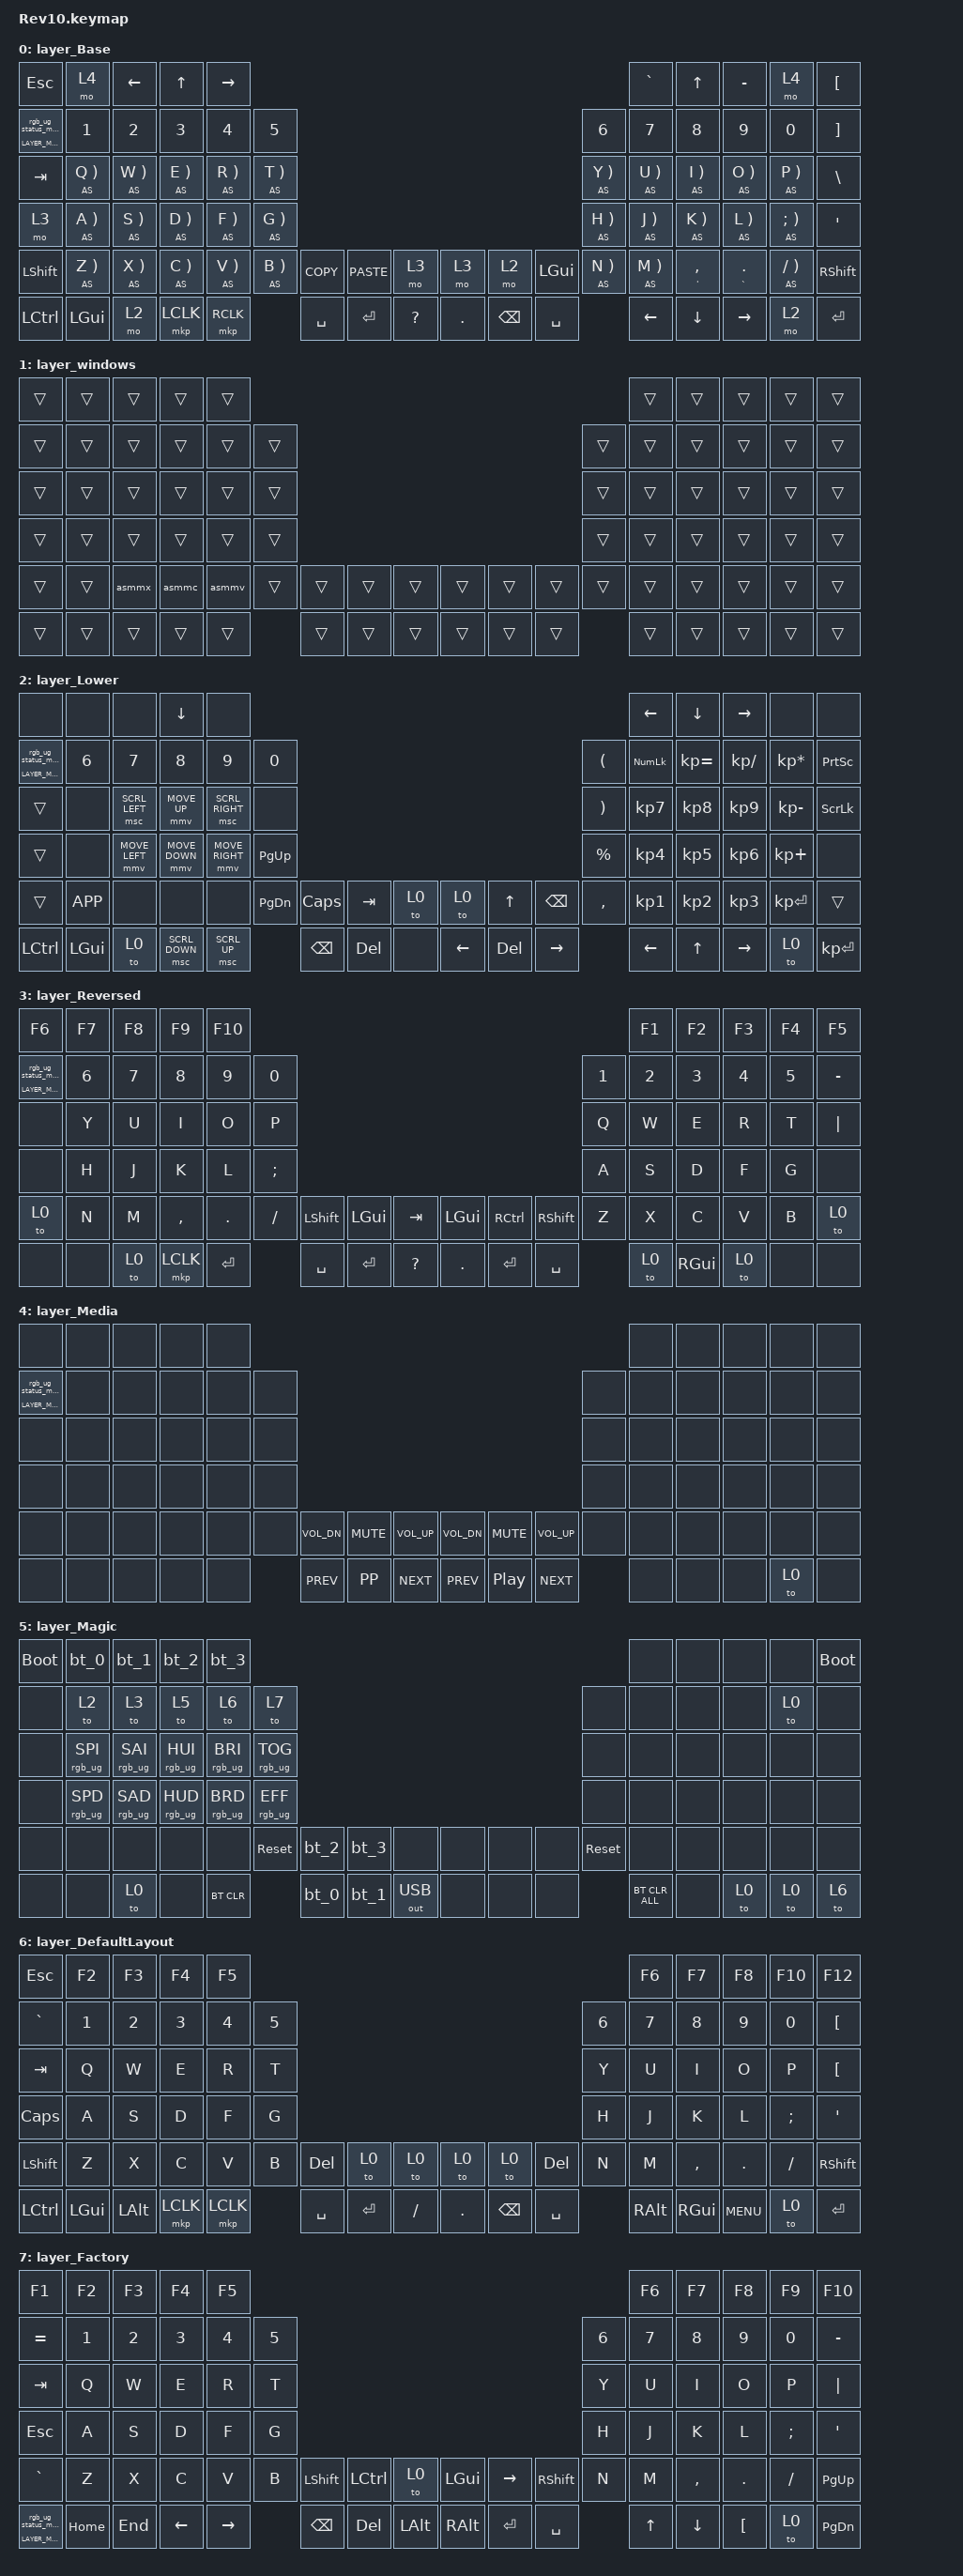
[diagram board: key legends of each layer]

/*
 * Copyright (c) 2020 The ZMK Contributors
 * Copyright (c) 2023 Innaworks Development Limited, trading as MoErgo
 *
 * SPDX-License-Identifier: MIT
 */


/* THIS FILE WAS GENERATED BY GLOVE80 LAYOUT EDITOR
 *
 * This file was generated automatically. You may or may not want to
 * edit it directly.
 */

#include <behaviors.dtsi>
/* Include all behavior includes needed */
#include <dt-bindings/zmk/outputs.h>
#include <dt-bindings/zmk/keys.h>
#include <dt-bindings/zmk/bt.h>
#include <dt-bindings/zmk/rgb.h>

/* Automatically generated layer name #define */
#define LAYER_Base 0
#define LAYER_windows 1
#define LAYER_Lower 2
#define LAYER_Reversed 3
#define LAYER_Media 4
#define LAYER_Magic 5
#define LAYER_DefaultLayout 6
#define LAYER_Factory 7

/* To deal with the situation where there is no Lower layer, to keep &lower happy */
#ifndef LAYER_Lower
#define LAYER_Lower 0
#endif

/* Custom Device-tree */
// KEY_REPEATING_TERM defines how much time you have left (milliseconds)
// after tapping a key to hold it again in order to make it auto-repeat.
#define KEY_REPEATING_TERM 300 // "tap then hold" for key auto-repeat

// TAPPING_TERM defines how long you need to hold (milliseconds)
// mod keys in order to send their modifiers to the computer
// (i.e. "register" them) for mod-click mouse usage (e.g. Ctrl-Click).
#define TAPPING_TERM 260 // TAPPING_TERM + ALLOW_CROSSOVER_AFTER
    
// AUTO_SHIFT_TERM defines how long you need to hold (milliseconds)
// a key in order to send its shifted version to the computer.
#define AUTO_SHIFT_TERM 200 // AUTO_SHIFT_TERM + ALLOW_CROSSOVER_AFTER

&mt {
    flavor = "hold-preferred";
    tapping-term-ms = <TAPPING_TERM>;
    quick-tap-ms = <KEY_REPEATING_TERM>;
};

&lt {
    flavor = "hold-preferred";
    tapping-term-ms = <TAPPING_TERM>;
    quick-tap-ms = <KEY_REPEATING_TERM>;
};


/* Glove80 system behavior & macros */
/ {
    behaviors {
        // For the "layer" key, it'd nice to be able to use it as either a shift or a toggle.
        // Configure it as a tap dance, so the first tap (or hold) is a &mo and the second tap is a &to
        lower: lower {
            compatible = "zmk,behavior-tap-dance";
            label = "LAYER_TAP_DANCE";
            #binding-cells = <0>;
            tapping-term-ms = <200>;
            bindings = <&mo LAYER_Lower>, <&to LAYER_Lower>;
        };
    };
};

/ {
    macros {
        rgb_ug_status_macro: rgb_ug_status_macro {
            label = "RGB_UG_STATUS";
            compatible = "zmk,behavior-macro";
            #binding-cells = <0>;
            bindings
                = <&rgb_ug RGB_STATUS>;
        };
    };
};


/ {
#ifdef BT_DISC_CMD
    behaviors {
        bt_0: bt_0 {
            compatible = "zmk,behavior-tap-dance";
            label = "BT_0";
            #binding-cells = <0>;
            tapping-term-ms = <200>;
            bindings = <&bt_select_0>, <&bt BT_DISC 0>;
        };
        bt_1: bt_1 {
            compatible = "zmk,behavior-tap-dance";
            label = "BT_1";
            #binding-cells = <0>;
            tapping-term-ms = <200>;
            bindings = <&bt_select_1>, <&bt BT_DISC 1>;
        };
        bt_2: bt_2 {
            compatible = "zmk,behavior-tap-dance";
            label = "BT_2";
            #binding-cells = <0>;
            tapping-term-ms = <200>;
            bindings = <&bt_select_2>, <&bt BT_DISC 2>;
        };
        bt_3: bt_3 {
            compatible = "zmk,behavior-tap-dance";
            label = "BT_3";
            #binding-cells = <0>;
            tapping-term-ms = <200>;
            bindings = <&bt_select_3>, <&bt BT_DISC 3>;
        };
    };
    macros {
        bt_select_0: bt_select_0 {
            label = "BT_SELECT_0";
            compatible = "zmk,behavior-macro";
            #binding-cells = <0>;
            bindings
                = <&out OUT_BLE>,
                  <&bt BT_SEL 0>;
        };
        bt_select_1: bt_select_1 {
            label = "BT_SELECT_1";
            compatible = "zmk,behavior-macro";
            #binding-cells = <0>;
            bindings
                = <&out OUT_BLE>,
                  <&bt BT_SEL 1>;
        };
        bt_select_2: bt_select_2 {
            label = "BT_SELECT_2";
            compatible = "zmk,behavior-macro";
            #binding-cells = <0>;
            bindings
                = <&out OUT_BLE>,
                  <&bt BT_SEL 2>;
        };
        bt_select_3: bt_select_3 {
            label = "BT_SELECT_3";
            compatible = "zmk,behavior-macro";
            #binding-cells = <0>;
            bindings
                = <&out OUT_BLE>,
                  <&bt BT_SEL 3>;
        };
    };
#else
    macros {
        bt_0: bt_0 {
            label = "BT_0";
            compatible = "zmk,behavior-macro";
            #binding-cells = <0>;
            bindings
                = <&out OUT_BLE>,
                  <&bt BT_SEL 0>;
        };
        bt_1: bt_1 {
            label = "BT_1";
            compatible = "zmk,behavior-macro";
            #binding-cells = <0>;
            bindings
                = <&out OUT_BLE>,
                  <&bt BT_SEL 1>;
        };
        bt_2: bt_2 {
            label = "BT_2";
            compatible = "zmk,behavior-macro";
            #binding-cells = <0>;
            bindings
                = <&out OUT_BLE>,
                  <&bt BT_SEL 2>;
        };
        bt_3: bt_3 {
            label = "BT_3";
            compatible = "zmk,behavior-macro";
            #binding-cells = <0>;
            bindings
                = <&out OUT_BLE>,
                  <&bt BT_SEL 3>;
        };
    };
#endif
};

/ {
    behaviors {
        magic: magic {
            compatible = "zmk,behavior-hold-tap";
            label = "MAGIC_HOLD_TAP";
            #binding-cells = <2>;
            flavor = "tap-preferred";
            tapping-term-ms = <200>;
            bindings = <&mo>, <&rgb_ug_status_macro>;
        };
    };
};

/* #define for key positions */
#define POS_LH_T1 52
#define POS_LH_T2 53
#define POS_LH_T3 54
#define POS_LH_T4 69
#define POS_LH_T5 70
#define POS_LH_T6 71
#define POS_LH_C1R2 15
#define POS_LH_C1R3 27
#define POS_LH_C1R4 39
#define POS_LH_C1R5 51
#define POS_LH_C2R1 4
#define POS_LH_C2R2 14
#define POS_LH_C2R3 26
#define POS_LH_C2R4 38
#define POS_LH_C2R5 50
#define POS_LH_C2R6 68
#define POS_LH_C3R1 3
#define POS_LH_C3R2 13
#define POS_LH_C3R3 25
#define POS_LH_C3R4 37
#define POS_LH_C3R5 49
#define POS_LH_C3R6 67
#define POS_LH_C4R1 2
#define POS_LH_C4R2 12
#define POS_LH_C4R3 24
#define POS_LH_C4R4 36
#define POS_LH_C4R5 48
#define POS_LH_C4R6 66
#define POS_LH_C5R1 1
#define POS_LH_C5R2 11
#define POS_LH_C5R3 23
#define POS_LH_C5R4 35
#define POS_LH_C5R5 47
#define POS_LH_C5R6 65
#define POS_LH_C6R1 0
#define POS_LH_C6R2 10
#define POS_LH_C6R3 22
#define POS_LH_C6R4 34
#define POS_LH_C6R5 46
#define POS_LH_C6R6 64
#define POS_RH_T1 57
#define POS_RH_T2 56
#define POS_RH_T3 55
#define POS_RH_T4 74
#define POS_RH_T5 73
#define POS_RH_T6 72
#define POS_RH_C1R2 16
#define POS_RH_C1R3 28
#define POS_RH_C1R4 40
#define POS_RH_C1R5 58
#define POS_RH_C2R1 5
#define POS_RH_C2R2 17
#define POS_RH_C2R3 29
#define POS_RH_C2R4 41
#define POS_RH_C2R5 59
#define POS_RH_C2R6 75
#define POS_RH_C3R1 6
#define POS_RH_C3R2 18
#define POS_RH_C3R3 30
#define POS_RH_C3R4 42
#define POS_RH_C3R5 60
#define POS_RH_C3R6 76
#define POS_RH_C4R1 7
#define POS_RH_C4R2 19
#define POS_RH_C4R3 31
#define POS_RH_C4R4 43
#define POS_RH_C4R5 61
#define POS_RH_C4R6 77
#define POS_RH_C5R1 8
#define POS_RH_C5R2 20
#define POS_RH_C5R3 32
#define POS_RH_C5R4 44
#define POS_RH_C5R5 62
#define POS_RH_C5R6 78
#define POS_RH_C6R1 9
#define POS_RH_C6R2 21
#define POS_RH_C6R3 33
#define POS_RH_C6R4 45
#define POS_RH_C6R5 63
#define POS_RH_C6R6 79

/* Custom Defined Behaviors */
/ {
// NOTE: Use the `#define` settings below to customize this keymap!
// For example, here are the main optional features you can enable:
#define DIFFICULTY_LEVEL  1 // 0:custom, 1:easy -> 5:hard (see below)
// TIP: Add more setting overrides here instead of editing them below.

//////////////////////////////////////////////////////////////////////////////
//
// Advanced Home Row Mods (HRM) Example based on
// Sunaku's Keymap v35 -- "Glorious Engrammer"
// - https://github.com/sunaku/glove80-keymaps
//
//////////////////////////////////////////////////////////////////////////////

//
// DIFFICULTY_LEVEL specifies your level of expertise with this keymap.
// It's meant to help newcomers gradually work their way up to mastery.
// You can disable this setting by omitting it or assigning a `0` zero.
//
// #define DIFFICULTY_LEVEL 0 // custom (see defaults below)
// #define DIFFICULTY_LEVEL 1 // novice (500ms)
// #define DIFFICULTY_LEVEL 2 // slower (400ms)
// #define DIFFICULTY_LEVEL 3 // normal (300ms)
// #define DIFFICULTY_LEVEL 4 // faster (200ms)
// #define DIFFICULTY_LEVEL 5 // expert (100ms)
//
#if defined(DIFFICULTY_LEVEL) && DIFFICULTY_LEVEL > 0
#define DIFFICULTY_THRESHOLD ((6-DIFFICULTY_LEVEL)*100)
#ifndef HOMEY_HOLDING_TIME
#define HOMEY_HOLDING_TIME DIFFICULTY_THRESHOLD
#endif
#ifndef INDEX_HOLDING_TIME
#define INDEX_HOLDING_TIME DIFFICULTY_THRESHOLD
#endif
#endif

behaviors {

    //////////////////////////////////////////////////////////////////////////
    //
    // Miryoku layers and home row mods (ported from my QMK endgame)
    // - https://sunaku.github.io/home-row-mods.html#porting-to-zmk
    // - https://github.com/urob/zmk-config#timeless-homerow-mods
    //
    //////////////////////////////////////////////////////////////////////////

    //
    // HOMEY_HOLDING_TYPE defines the flavor of ZMK hold-tap behavior to use
    // for the pinky, ring, and middle fingers (which are assigned to Super,
    // Alt, and Ctrl respectively in the Miryoku system) on home row keys.
    //
    #ifndef HOMEY_HOLDING_TYPE
    #define HOMEY_HOLDING_TYPE "tap-preferred"
    #endif

    //
    // HOMEY_HOLDING_TIME defines how long you need to hold (milliseconds)
    // home row mod keys in order to send their modifiers to the computer
    // (i.e. "register" them) for mod-click mouse usage (e.g. Ctrl-Click).
    //
    #ifndef HOMEY_HOLDING_TIME
    #define HOMEY_HOLDING_TIME 270 // TAPPING_TERM + ALLOW_CROSSOVER_AFTER
    #endif

    //
    // HOMEY_STREAK_DECAY defines how long you need to wait (milliseconds)
    // after typing before you can use home row mods again.  It prevents
    // unintended activation of home row mods when you're actively typing.
    //
    #ifndef HOMEY_STREAK_DECAY
    #define HOMEY_STREAK_DECAY 250
    #endif

    //
    // HOMEY_REPEAT_DECAY defines how much time you have left (milliseconds)
    // after tapping a key to hold it again in order to make it auto-repeat.
    //
    #ifndef HOMEY_REPEAT_DECAY
    #define HOMEY_REPEAT_DECAY 300 // "tap then hold" for key auto-repeat
    #endif

    //
    // INDEX_HOLDING_TYPE defines the flavor of ZMK hold-tap behavior to use
    // for index fingers (which Miryoku assigns to Shift) on home row keys.
    //
    #ifndef INDEX_HOLDING_TYPE
    #define INDEX_HOLDING_TYPE "tap-preferred"
    #endif

    //
    // INDEX_HOLDING_TIME defines how long you need to hold (milliseconds)
    // index finger keys in order to send their modifiers to the computer
    // (i.e. "register" them) for mod-click mouse usage (e.g. Shift-Click).
    //
    #ifndef INDEX_HOLDING_TIME
    #define INDEX_HOLDING_TIME 170
    #endif

    //
    // INDEX_STREAK_DECAY defines how long you need to wait (milliseconds)
    // after typing before you can use home row mods again.  It prevents
    // unintended activation of home row mods when you're actively typing.
    //
    #ifndef INDEX_STREAK_DECAY
    #define INDEX_STREAK_DECAY 150
    #endif

    //
    // INDEX_REPEAT_DECAY defines how much time you have left (milliseconds)
    // after tapping a key to hold it again in order to make it auto-repeat.
    //
    #ifndef INDEX_REPEAT_DECAY
    #define INDEX_REPEAT_DECAY 300 // "tap then hold" for key auto-repeat
    #endif

    //
    // Glove80 key positions index for positional hold-tap
    // - https://discord.com/channels/877392805654306816/937645688244826154/1066713913351221248
    // - https://media.discordapp.net/attachments/937645688244826154/1066713913133121556/image.png
    //
    // |------------------------|------------------------|
    // | LEFT_HAND_KEYS         |        RIGHT_HAND_KEYS |
    // |                        |                        |
    // |  0  1  2  3  4         |          5  6  7  8  9 |
    // | 10 11 12 13 14 15      |      16 17 18 19 20 21 |
    // | 22 23 24 25 26 27      |      28 29 30 31 32 33 |
    // | 34 35 36 37 38 39      |      40 41 42 43 44 45 |
    // | 46 47 48 49 50 51      |      58 59 60 61 62 63 |
    // | 64 65 66 67 68         |         75 76 77 78 79 |
    // |                69 52   |   57 74                |
    // |                 70 53  |  56 73                 |
    // |                  71 54 | 55 72                  |
    // |------------------------|------------------------|
    //
    #define LEFT_HAND_KEYS      \
          0  1  2  3  4         \
         10 11 12 13 14 15      \
         22 23 24 25 26 27      \
         34 35 36 37 38 39      \
         46 47 48 49 50 51      \
         64 65 66 67 68
    #define RIGHT_HAND_KEYS     \
                                           5  6  7  8  9 \
                                       16 17 18 19 20 21 \
                                       28 29 30 31 32 33 \
                                       40 41 42 43 44 45 \
                                       58 59 60 61 62 63 \
                                          75 76 77 78 79
    #define THUMB_KEYS          \
                        69 52       57 74                \
                         70 53     56 73                 \
                          71 54   55 72

    //
    // Home row mods with per-finger configuration settings
    //
    #ifndef PINKY_HOLDING_TYPE
    #define PINKY_HOLDING_TYPE HOMEY_HOLDING_TYPE
    #endif
    #ifndef PINKY_HOLDING_TIME
    #define PINKY_HOLDING_TIME HOMEY_HOLDING_TIME
    #endif
    #ifndef PINKY_STREAK_DECAY
    #define PINKY_STREAK_DECAY HOMEY_STREAK_DECAY
    #endif
    #ifndef PINKY_REPEAT_DECAY
    #define PINKY_REPEAT_DECAY HOMEY_REPEAT_DECAY
    #endif
    #ifndef RING1_HOLDING_TYPE
    #define RING1_HOLDING_TYPE HOMEY_HOLDING_TYPE
    #endif
    #ifndef RING1_HOLDING_TIME
    #define RING1_HOLDING_TIME HOMEY_HOLDING_TIME
    #endif
    #ifndef RING1_STREAK_DECAY
    #define RING1_STREAK_DECAY HOMEY_STREAK_DECAY
    #endif
    #ifndef RING1_REPEAT_DECAY
    #define RING1_REPEAT_DECAY HOMEY_REPEAT_DECAY
    #endif
    #ifndef RING2_HOLDING_TYPE
    #define RING2_HOLDING_TYPE HOMEY_HOLDING_TYPE
    #endif
    #ifndef RING2_HOLDING_TIME
    #define RING2_HOLDING_TIME HOMEY_HOLDING_TIME
    #endif
    #ifndef RING2_STREAK_DECAY
    #define RING2_STREAK_DECAY HOMEY_STREAK_DECAY
    #endif
    #ifndef RING2_REPEAT_DECAY
    #define RING2_REPEAT_DECAY HOMEY_REPEAT_DECAY
    #endif
    #ifndef MIDDY_HOLDING_TYPE
    #define MIDDY_HOLDING_TYPE HOMEY_HOLDING_TYPE
    #endif
    #ifndef MIDDY_HOLDING_TIME
    #define MIDDY_HOLDING_TIME HOMEY_HOLDING_TIME
    #endif
    #ifndef MIDDY_STREAK_DECAY
    #define MIDDY_STREAK_DECAY HOMEY_STREAK_DECAY
    #endif
    #ifndef MIDDY_REPEAT_DECAY
    #define MIDDY_REPEAT_DECAY HOMEY_REPEAT_DECAY
    #endif
    #ifndef INDEX_HOLDING_TYPE
    #define INDEX_HOLDING_TYPE HOMEY_HOLDING_TYPE
    #endif
    #ifndef INDEX_HOLDING_TIME
    #define INDEX_HOLDING_TIME HOMEY_HOLDING_TIME
    #endif
    #ifndef INDEX_STREAK_DECAY
    #define INDEX_STREAK_DECAY HOMEY_STREAK_DECAY
    #endif
    #ifndef INDEX_REPEAT_DECAY
    #define INDEX_REPEAT_DECAY HOMEY_REPEAT_DECAY
    #endif
    #ifndef LEFT_PINKY_HOLDING_TYPE
    #define LEFT_PINKY_HOLDING_TYPE PINKY_HOLDING_TYPE
    #endif
    #ifndef LEFT_PINKY_HOLDING_TIME
    #define LEFT_PINKY_HOLDING_TIME PINKY_HOLDING_TIME
    #endif
    #ifndef LEFT_PINKY_STREAK_DECAY
    #define LEFT_PINKY_STREAK_DECAY PINKY_STREAK_DECAY
    #endif
    #ifndef LEFT_PINKY_REPEAT_DECAY
    #define LEFT_PINKY_REPEAT_DECAY PINKY_REPEAT_DECAY
    #endif
    left_pinky: homey_left_pinky {
        compatible = "zmk,behavior-hold-tap";
        flavor = LEFT_PINKY_HOLDING_TYPE;
        hold-trigger-key-positions = <RIGHT_HAND_KEYS THUMB_KEYS>;
        hold-trigger-on-release; // wait for other home row mods
        tapping-term-ms = <LEFT_PINKY_HOLDING_TIME>;
        quick-tap-ms = <LEFT_PINKY_REPEAT_DECAY>;
        require-prior-idle-ms = <LEFT_PINKY_STREAK_DECAY>;
        #binding-cells = <2>;
        bindings = <&kp>, <&kp>;
    };
    #ifndef RIGHT_PINKY_HOLDING_TYPE
    #define RIGHT_PINKY_HOLDING_TYPE PINKY_HOLDING_TYPE
    #endif
    #ifndef RIGHT_PINKY_HOLDING_TIME
    #define RIGHT_PINKY_HOLDING_TIME PINKY_HOLDING_TIME
    #endif
    #ifndef RIGHT_PINKY_STREAK_DECAY
    #define RIGHT_PINKY_STREAK_DECAY PINKY_STREAK_DECAY
    #endif
    #ifndef RIGHT_PINKY_REPEAT_DECAY
    #define RIGHT_PINKY_REPEAT_DECAY PINKY_REPEAT_DECAY
    #endif
    right_pinky: homey_right_pinky {
        compatible = "zmk,behavior-hold-tap";
        flavor = RIGHT_PINKY_HOLDING_TYPE;
        hold-trigger-key-positions = <LEFT_HAND_KEYS THUMB_KEYS>;
        hold-trigger-on-release; // wait for other home row mods
        tapping-term-ms = <RIGHT_PINKY_HOLDING_TIME>;
        quick-tap-ms = <RIGHT_PINKY_REPEAT_DECAY>;
        require-prior-idle-ms = <RIGHT_PINKY_STREAK_DECAY>;
        #binding-cells = <2>;
        bindings = <&kp>, <&kp>;
    };
    #ifndef LEFT_RING1_HOLDING_TYPE
    #define LEFT_RING1_HOLDING_TYPE RING1_HOLDING_TYPE
    #endif
    #ifndef LEFT_RING1_HOLDING_TIME
    #define LEFT_RING1_HOLDING_TIME RING1_HOLDING_TIME
    #endif
    #ifndef LEFT_RING1_STREAK_DECAY
    #define LEFT_RING1_STREAK_DECAY RING1_STREAK_DECAY
    #endif
    #ifndef LEFT_RING1_REPEAT_DECAY
    #define LEFT_RING1_REPEAT_DECAY RING1_REPEAT_DECAY
    #endif
    left_ring1: homey_left_ring1 {
        compatible = "zmk,behavior-hold-tap";
        flavor = LEFT_RING1_HOLDING_TYPE;
        hold-trigger-key-positions = <RIGHT_HAND_KEYS THUMB_KEYS>;
        hold-trigger-on-release; // wait for other home row mods
        tapping-term-ms = <LEFT_RING1_HOLDING_TIME>;
        quick-tap-ms = <LEFT_RING1_REPEAT_DECAY>;
        require-prior-idle-ms = <LEFT_RING1_STREAK_DECAY>;
        #binding-cells = <2>;
        bindings = <&kp>, <&kp>;
    };
    #ifndef RIGHT_RING1_HOLDING_TYPE
    #define RIGHT_RING1_HOLDING_TYPE RING1_HOLDING_TYPE
    #endif
    #ifndef RIGHT_RING1_HOLDING_TIME
    #define RIGHT_RING1_HOLDING_TIME RING1_HOLDING_TIME
    #endif
    #ifndef RIGHT_RING1_STREAK_DECAY
    #define RIGHT_RING1_STREAK_DECAY RING1_STREAK_DECAY
    #endif
    #ifndef RIGHT_RING1_REPEAT_DECAY
    #define RIGHT_RING1_REPEAT_DECAY RING1_REPEAT_DECAY
    #endif
    right_ring1: homey_right_ring1 {
        compatible = "zmk,behavior-hold-tap";
        flavor = RIGHT_RING1_HOLDING_TYPE;
        hold-trigger-key-positions = <LEFT_HAND_KEYS THUMB_KEYS>;
        hold-trigger-on-release; // wait for other home row mods
        tapping-term-ms = <RIGHT_RING1_HOLDING_TIME>;
        quick-tap-ms = <RIGHT_RING1_REPEAT_DECAY>;
        require-prior-idle-ms = <RIGHT_RING1_STREAK_DECAY>;
        #binding-cells = <2>;
        bindings = <&kp>, <&kp>;
    };
    #ifndef LEFT_RING2_HOLDING_TYPE
    #define LEFT_RING2_HOLDING_TYPE RING2_HOLDING_TYPE
    #endif
    #ifndef LEFT_RING2_HOLDING_TIME
    #define LEFT_RING2_HOLDING_TIME RING2_HOLDING_TIME
    #endif
    #ifndef LEFT_RING2_STREAK_DECAY
    #define LEFT_RING2_STREAK_DECAY RING2_STREAK_DECAY
    #endif
    #ifndef LEFT_RING2_REPEAT_DECAY
    #define LEFT_RING2_REPEAT_DECAY RING2_REPEAT_DECAY
    #endif
    left_ring2: homey_left_ring2 {
        compatible = "zmk,behavior-hold-tap";
        flavor = LEFT_RING2_HOLDING_TYPE;
        hold-trigger-key-positions = <RIGHT_HAND_KEYS THUMB_KEYS>;
        hold-trigger-on-release; // wait for other home row mods
        tapping-term-ms = <LEFT_RING2_HOLDING_TIME>;
        quick-tap-ms = <LEFT_RING2_REPEAT_DECAY>;
        require-prior-idle-ms = <LEFT_RING2_STREAK_DECAY>;
        #binding-cells = <2>;
        bindings = <&kp>, <&kp>;
    };
    #ifndef RIGHT_RING2_HOLDING_TYPE
    #define RIGHT_RING2_HOLDING_TYPE RING2_HOLDING_TYPE
    #endif
    #ifndef RIGHT_RING2_HOLDING_TIME
    #define RIGHT_RING2_HOLDING_TIME RING2_HOLDING_TIME
    #endif
    #ifndef RIGHT_RING2_STREAK_DECAY
    #define RIGHT_RING2_STREAK_DECAY RING2_STREAK_DECAY
    #endif
    #ifndef RIGHT_RING2_REPEAT_DECAY
    #define RIGHT_RING2_REPEAT_DECAY RING2_REPEAT_DECAY
    #endif
    right_ring2: homey_right_ring2 {
        compatible = "zmk,behavior-hold-tap";
        flavor = RIGHT_RING2_HOLDING_TYPE;
        hold-trigger-key-positions = <LEFT_HAND_KEYS THUMB_KEYS>;
        hold-trigger-on-release; // wait for other home row mods
        tapping-term-ms = <RIGHT_RING2_HOLDING_TIME>;
        quick-tap-ms = <RIGHT_RING2_REPEAT_DECAY>;
        require-prior-idle-ms = <RIGHT_RING2_STREAK_DECAY>;
        #binding-cells = <2>;
        bindings = <&kp>, <&kp>;
    };
    #ifndef LEFT_MIDDY_HOLDING_TYPE
    #define LEFT_MIDDY_HOLDING_TYPE MIDDY_HOLDING_TYPE
    #endif
    #ifndef LEFT_MIDDY_HOLDING_TIME
    #define LEFT_MIDDY_HOLDING_TIME MIDDY_HOLDING_TIME
    #endif
    #ifndef LEFT_MIDDY_STREAK_DECAY
    #define LEFT_MIDDY_STREAK_DECAY MIDDY_STREAK_DECAY
    #endif
    #ifndef LEFT_MIDDY_REPEAT_DECAY
    #define LEFT_MIDDY_REPEAT_DECAY MIDDY_REPEAT_DECAY
    #endif
    left_middy: homey_left_middy {
        compatible = "zmk,behavior-hold-tap";
        flavor = LEFT_MIDDY_HOLDING_TYPE;
        hold-trigger-key-positions = <RIGHT_HAND_KEYS THUMB_KEYS>;
        hold-trigger-on-release; // wait for other home row mods
        tapping-term-ms = <LEFT_MIDDY_HOLDING_TIME>;
        quick-tap-ms = <LEFT_MIDDY_REPEAT_DECAY>;
        require-prior-idle-ms = <LEFT_MIDDY_STREAK_DECAY>;
        #binding-cells = <2>;
        bindings = <&kp>, <&kp>;
    };
    #ifndef RIGHT_MIDDY_HOLDING_TYPE
    #define RIGHT_MIDDY_HOLDING_TYPE MIDDY_HOLDING_TYPE
    #endif
    #ifndef RIGHT_MIDDY_HOLDING_TIME
    #define RIGHT_MIDDY_HOLDING_TIME MIDDY_HOLDING_TIME
    #endif
    #ifndef RIGHT_MIDDY_STREAK_DECAY
    #define RIGHT_MIDDY_STREAK_DECAY MIDDY_STREAK_DECAY
    #endif
    #ifndef RIGHT_MIDDY_REPEAT_DECAY
    #define RIGHT_MIDDY_REPEAT_DECAY MIDDY_REPEAT_DECAY
    #endif
    right_middy: homey_right_middy {
        compatible = "zmk,behavior-hold-tap";
        flavor = RIGHT_MIDDY_HOLDING_TYPE;
        hold-trigger-key-positions = <LEFT_HAND_KEYS THUMB_KEYS>;
        hold-trigger-on-release; // wait for other home row mods
        tapping-term-ms = <RIGHT_MIDDY_HOLDING_TIME>;
        quick-tap-ms = <RIGHT_MIDDY_REPEAT_DECAY>;
        require-prior-idle-ms = <RIGHT_MIDDY_STREAK_DECAY>;
        #binding-cells = <2>;
        bindings = <&kp>, <&kp>;
    };
    #ifndef LEFT_INDEX_HOLDING_TYPE
    #define LEFT_INDEX_HOLDING_TYPE INDEX_HOLDING_TYPE
    #endif
    #ifndef LEFT_INDEX_HOLDING_TIME
    #define LEFT_INDEX_HOLDING_TIME INDEX_HOLDING_TIME
    #endif
    #ifndef LEFT_INDEX_STREAK_DECAY
    #define LEFT_INDEX_STREAK_DECAY INDEX_STREAK_DECAY
    #endif
    #ifndef LEFT_INDEX_REPEAT_DECAY
    #define LEFT_INDEX_REPEAT_DECAY INDEX_REPEAT_DECAY
    #endif
    left_index: homey_left_index {
        compatible = "zmk,behavior-hold-tap";
        flavor = LEFT_INDEX_HOLDING_TYPE;
        hold-trigger-key-positions = <RIGHT_HAND_KEYS THUMB_KEYS>;
        hold-trigger-on-release; // wait for other home row mods
        tapping-term-ms = <LEFT_INDEX_HOLDING_TIME>;
        quick-tap-ms = <LEFT_INDEX_REPEAT_DECAY>;
        require-prior-idle-ms = <LEFT_INDEX_STREAK_DECAY>;
        #binding-cells = <2>;
        bindings = <&kp>, <&kp>;
    };
    #ifndef RIGHT_INDEX_HOLDING_TYPE
    #define RIGHT_INDEX_HOLDING_TYPE INDEX_HOLDING_TYPE
    #endif
    #ifndef RIGHT_INDEX_HOLDING_TIME
    #define RIGHT_INDEX_HOLDING_TIME INDEX_HOLDING_TIME
    #endif
    #ifndef RIGHT_INDEX_STREAK_DECAY
    #define RIGHT_INDEX_STREAK_DECAY INDEX_STREAK_DECAY
    #endif
    #ifndef RIGHT_INDEX_REPEAT_DECAY
    #define RIGHT_INDEX_REPEAT_DECAY INDEX_REPEAT_DECAY
    #endif
    right_index: homey_right_index {
        compatible = "zmk,behavior-hold-tap";
        flavor = RIGHT_INDEX_HOLDING_TYPE;
        hold-trigger-key-positions = <LEFT_HAND_KEYS THUMB_KEYS>;
        hold-trigger-on-release; // wait for other home row mods
        tapping-term-ms = <RIGHT_INDEX_HOLDING_TIME>;
        quick-tap-ms = <RIGHT_INDEX_REPEAT_DECAY>;
        require-prior-idle-ms = <RIGHT_INDEX_STREAK_DECAY>;
        #binding-cells = <2>;
        bindings = <&kp>, <&kp>;
    };

};

//////////////////////////////////////////////////////////////////////////
//
// Mouse keys (control mouse via keyboard) -- requires PR23 beta firmware:
// select "community.pr23.mouse-keys" from the drop-down menu located at
// Glove80 Layout Editor > Settings > Advanced Settings > Firmware Version
//
// - https://github.com/moergo-sc/zmk/pull/23
// - https://gist.github.com/krissen/dd27082e7ab0575619c7a31f4d2ec7ae
// - https://github.com/zmkfirmware/zmk/compare/main...urob:zmk:mouse-3.2
//
//////////////////////////////////////////////////////////////////////////

//
// MOUSE_MOTION_DELAY defines how long to wait (milliseconds) before starting
// to move the mouse pointer.
//
#ifndef MOUSE_MOTION_DELAY
#define MOUSE_MOTION_DELAY 0
#endif

//
// MOUSE_MOTION_ACCELERATION_EXPONENT sets how the mouse pointer accelerates:
//
// acceleration exponent 0: uniform speed
// acceleration exponent 1: uniform acceleration
// acceleration exponent 2: uniform jerk
//
#ifndef MOUSE_MOTION_ACCELERATION_EXPONENT
#define MOUSE_MOTION_ACCELERATION_EXPONENT 1
#endif

//
// MOUSE_MOTION_TIME_TO_MAXIMUM_SPEED defines how long to wait (milliseconds)
// before the mouse pointer speed is suddenly boosted to the maximum value.
//
#ifndef MOUSE_MOTION_TIME_TO_MAXIMUM_SPEED
#define MOUSE_MOTION_TIME_TO_MAXIMUM_SPEED 300
#endif

//
// MOUSE_MOTION_MAXIMUM_SPEED defines how quickly the mouse pointer can move.
//
#ifndef MOUSE_MOTION_MAXIMUM_SPEED
#define MOUSE_MOTION_MAXIMUM_SPEED 600
#endif

//
// MOUSE_SCROLL_DELAY defines how long to wait (milliseconds) before starting
// to move the mouse pointer.
//
#ifndef MOUSE_SCROLL_DELAY
#define MOUSE_SCROLL_DELAY 0
#endif

//
// MOUSE_SCROLL_ACCELERATION_EXPONENT sets how the mouse pointer accelerates:
//
// acceleration exponent 0: uniform speed
// acceleration exponent 1: uniform acceleration
// acceleration exponent 2: uniform jerk
//
#ifndef MOUSE_SCROLL_ACCELERATION_EXPONENT
#define MOUSE_SCROLL_ACCELERATION_EXPONENT 0
#endif

//
// MOUSE_SCROLL_TIME_TO_MAXIMUM_SPEED defines how long to wait (milliseconds)
// before the mouse pointer speed is suddenly boosted to the maximum value.
//
#ifndef MOUSE_SCROLL_TIME_TO_MAXIMUM_SPEED
#define MOUSE_SCROLL_TIME_TO_MAXIMUM_SPEED 300
#endif

//
// MOUSE_SCROLL_MAXIMUM_SPEED defines how quickly the mouse wheel can scroll.
//
#ifndef MOUSE_SCROLL_MAXIMUM_SPEED
#define MOUSE_SCROLL_MAXIMUM_SPEED 10
#endif
/*HACK*/};
#if __has_include(<zmk/events/mouse_tick.h>)
    // ==== MOUSE-KEY <section begins> ====
    #define ZMK_MOUSE_DEFAULT_MOVE_VAL MOUSE_MOTION_MAXIMUM_SPEED
    #define ZMK_MOUSE_DEFAULT_SCRL_VAL MOUSE_SCROLL_MAXIMUM_SPEED
    #include <dt-bindings/zmk/mouse.h>
    &mmv {
      delay-ms = <MOUSE_MOTION_DELAY>;
      acceleration-exponent = <MOUSE_MOTION_ACCELERATION_EXPONENT>;
      time-to-max-speed-ms = <MOUSE_MOTION_TIME_TO_MAXIMUM_SPEED>;
    };
    &msc {
      delay-ms = <MOUSE_SCROLL_DELAY>;
      acceleration-exponent = <MOUSE_SCROLL_ACCELERATION_EXPONENT>;
      time-to-max-speed-ms = <MOUSE_SCROLL_TIME_TO_MAXIMUM_SPEED>;
    };
    // ==== MOUSE-KEY <section ends> =====
#else
    #define mkp none
    #define mmv none
    #define msc none
    #define LCLK
    #define MCLK
    #define RCLK
    #define MB1
    #define MB2
    #define MB3
    #define MB4
    #define MB5
    #define MB6
    #define MB7
    #define MB8
    #define MOVE_UP
    #define MOVE_DOWN
    #define MOVE_LEFT
    #define MOVE_RIGHT
    #define SCRL_UP
    #define SCRL_DOWN
    #define SCRL_LEFT
    #define SCRL_RIGHT
#endif
/*HACK*//{

conditional_layers {
  compatible = "zmk,conditional-layers";
  mac {
    if-layers = <LAYER_Mac_>;
    then-layer = <LAYER_Mac>;
  };
  raise {
    if-layers = <LAYER_Raise_>;
    then-layer = <LAYER_Raise>;
  };
  raise_mac {
    if-layers = <LAYER_Raise_ LAYER_Mac_>;
    then-layer = <LAYER_Raise_Mac>;
  };
  combined {
    if-layers = <LAYER_Lower LAYER_Raise>;
    then-layer = <LAYER_Combined>;
  };
  combined_one_btn {
    if-layers = <LAYER_Combined_>;
    then-layer = <LAYER_Combined>;
  };
};

behaviors {
  // Hold for modifier, tap to toggle layer
  mtog: mod_toggle {
    compatible = "zmk,behavior-hold-tap";
    #binding-cells = <2>;
    flavor = "hold-preferred";
    tapping-term-ms = <TAPPING_TERM>;
    quick-tap-ms = <KEY_REPEATING_TERM>;
    bindings = <&kp>, <&tog>;
  };

  //Tap for key press, hold to toggle layer
  ttog: tap_toggle {
    compatible = "zmk,behavior-hold-tap";
    #binding-cells = <2>;
    flavor = "hold-preferred";
    tapping-term-ms = <TAPPING_TERM>;
    quick-tap-ms = <KEY_REPEATING_TERM>;
    bindings = <&tog>, <&kp>;
  };

  // Shifted version of a key on a long press
  #define AS(keycode) as LS(keycode) keycode
  as: auto_shift {
    compatible = "zmk,behavior-hold-tap";
    #binding-cells = <2>;
    flavor = "tap-preferred";
    tapping_term_ms = <AUTO_SHIFT_TERM>;
    quick_tap_ms = <KEY_REPEATING_TERM>;
    bindings = <&kp>, <&kp>;
  };
   
  // mac Alex Add Custom hold-tap behavior to send LGUI plus key on hold
  #define LGUI_TAP(keycode) lgui_tap LGUI(keycode) keycode

    lgui_tap: lgui_tap_behavior {
    compatible = "zmk,behavior-hold-tap";
    #binding-cells = <2>;
    flavor = "tap-preferred"; // Preferred behavior on tap
    tapping_term_ms = <TAPPING_TERM>; // Time threshold for deciding tap vs hold
    quick_tap_ms = <150>;     // Time threshold for quick tap
    bindings = <&kp>, <&kp LGUI>; // Tap sends key, hold sends LGUI + key
  };
  
// Custom hold-tap behavior to toggle a layer on hold
    #define LAYER_TAP(layer, keycode) layer_tap layer keycode

    layer_tap: layer_tap_behavior {
    compatible = "zmk,behavior-hold-tap";
    #binding-cells = <2>;
    flavor = "tap-preferred"; // Preferred behavior on tap
    tapping_term_ms = <200>;  // Time threshold for deciding tap vs hold
    quick_tap_ms = <150>;     // Time threshold for quick tap
    bindings = <&kp>, <&mo>;  // Tap sends key, hold toggles layer
     };

    // Example usage: Toggles a layer on hold and sends 'A' on tap
    //&layer_tap 1 &kp A; // Adjust the layer number and keycode as needed

    // X shifted version on a long press, CUT when GUI modified
    asmmx: auto_shift_mod_morph_x {
    compatible = "zmk,behavior-mod-morph";
    #binding-cells = <0>;
    bindings = <&AS(X)>, <&kp K_CUT>;
    mods = <(MOD_LGUI)>;
    keep-mods = <(MOD_LGUI)>;
    };

  // C shifted version on a long press, COPY when GUI modified
  asmmc: auto_shift_mod_morph_c {
    compatible = "zmk,behavior-mod-morph";
    #binding-cells = <0>;
    bindings = <&AS(C)>, <&kp K_COPY>;
    mods = <(MOD_LGUI)>;
    keep-mods = <(MOD_LGUI)>;
  };

  // V shifted version on a long press, PASTE when GUI modified
  asmmv: auto_shift_mod_morph_v {
    compatible = "zmk,behavior-mod-morph";
    #binding-cells = <0>;
    bindings = <&AS(V)>, <&kp K_PASTE>;
    mods = <(MOD_LGUI)>;
    keep-mods = <(MOD_LGUI)>;
  };

  // Hold for a key, Caps Lock on a tap - pass dummy parameter value for caps_lock
  hcl: hold_caps_lock {
      compatible = "zmk,behavior-hold-tap";
      #binding-cells = <2>;
      flavor = "hold-preferred";
      tapping_term_ms = <TAPPING_TERM>;
      bindings = <&kp>, <&caps_lock>;
  };
  
  // Hold for a key, Caps Word on a tap - pass dummy parameter value for caps_word
  hcw: hold_caps_word {
      compatible = "zmk,behavior-hold-tap";
      #binding-cells = <2>;
      flavor = "hold-preferred";
      tapping_term_ms = <TAPPING_TERM>;
      bindings = <&kp>, <&caps_word>;
  };
};

macros {
  // Caps lock with a brief paused hold, for MacOS
  caps_lock: caps_lock {
    compatible = "zmk,behavior-macro";
    #binding-cells = <0>;
    tap-ms = <100>;
    wait-ms = <0>;
    bindings
    = <&macro_tap &kp CAPSLOCK>
    ;
  };

  // Function arrow: =>
  func_arrow: function_arrow {
    compatible = "zmk,behavior-macro";
    label = "FUNCTION_ARROW";
    #binding-cells = <0>;
    tap-ms = <0>;
    wait-ms = <0>;
    bindings
    = <&macro_tap &kp EQUAL &kp GREATER_THAN>
    ;
};

/* Automatically generated macro definitions */
/ {
    macros {
        unpst: unpst {
            label = "&UNPST";
            compatible = "zmk,behavior-macro";
            #binding-cells = <0>;
            tap-ms = <50>;
            wait-ms = <200>;
            bindings
                = <&kp A>
                , <&kp W>
                , <&kp S>
                , <&kp V>;
        };
    Xselall: Xselall {
            label = "&XSELALL";
            compatible = "zmk,behavior-macro";
            #binding-cells = <0>;
            
            
            bindings
                = <&kp LGUI>
                , <&kp A>;
        };
    };
};

/* Automatically generated combos definitions */
/ {
    combos {
            compatible = "zmk,combos";
    };
};

/* Automatically generated keymap */
/ {
    keymap {
        compatible = "zmk,keymap";


        layer_Base {
            bindings = <
              &kp ESC     &mo 4  &kp LEFT     &kp UP  &kp RIGHT                                                                                      &kp GRAVE          &kp UP      &kp MINUS       &mo 4   &kp LBKT
 &magic LAYER_Magic 0    &kp N1    &kp N2     &kp N3     &kp N4   &kp N5                                                                     &kp N6     &kp N7          &kp N8         &kp N9      &kp N0   &kp RBKT
              &kp TAB   &AS (Q)   &AS (W)    &AS (E)    &AS (R)  &AS (T)                                                                    &AS (Y)    &AS (U)         &AS (I)        &AS (O)     &AS (P)   &kp BSLH
                &mo 3   &AS (A)   &AS (S)    &AS (D)    &AS (F)  &AS (G)                                                                    &AS (H)    &AS (J)         &AS (K)        &AS (L)  &AS (SEMI)    &kp SQT
            &kp LSHFT   &AS (Z)   &AS (X)    &AS (C)    &AS (V)  &AS (B)  &kp K_COPY  &kp K_PASTE      &mo 3    &mo 3     &mo 2   &kp LGUI  &AS (N)    &AS (M)  &as APOS COMMA  &as GRAVE DOT  &AS (FSLH)  &kp RSHFT
            &kp LCTRL  &kp LGUI     &mo 2  &mkp LCLK  &mkp RCLK            &kp SPACE      &kp RET  &kp QMARK  &kp DOT  &kp BSPC  &kp SPACE            &kp LEFT        &kp DOWN      &kp RIGHT       &mo 2    &kp RET
            >;
        };

        layer_windows {
            bindings = <
 &trans  &trans  &trans  &trans  &trans                                                                  &trans  &trans  &trans  &trans  &trans
 &trans  &trans  &trans  &trans  &trans  &trans                                                  &trans  &trans  &trans  &trans  &trans  &trans
 &trans  &trans  &trans  &trans  &trans  &trans                                                  &trans  &trans  &trans  &trans  &trans  &trans
 &trans  &trans  &trans  &trans  &trans  &trans                                                  &trans  &trans  &trans  &trans  &trans  &trans
 &trans  &trans  &asmmx  &asmmc  &asmmv  &trans  &trans  &trans  &trans  &trans  &trans  &trans  &trans  &trans  &trans  &trans  &trans  &trans
 &trans  &trans  &trans  &trans  &trans          &trans  &trans  &trans  &trans  &trans  &trans          &trans  &trans  &trans  &trans  &trans
            >;
        };

        layer_Lower {
            bindings = <
                &none      &none           &none        &kp DOWN            &none                                                                                               &kp LEFT      &kp DOWN     &kp RIGHT            &none            &none
 &magic LAYER_Magic 0     &kp N6          &kp N7          &kp N8           &kp N9     &kp N0                                                            &kp LEFT_PARENTHESIS  &kp KP_NUM  &kp KP_EQUAL  &kp KP_SLASH  &kp KP_MULTIPLY  &kp PRINTSCREEN
               &trans      &none  &msc SCRL_LEFT    &mmv MOVE_UP  &msc SCRL_RIGHT      &none                                                           &kp RIGHT_PARENTHESIS   &kp KP_N7     &kp KP_N8     &kp KP_N9     &kp KP_MINUS   &kp SCROLLLOCK
               &trans      &none  &mmv MOVE_LEFT  &mmv MOVE_DOWN  &mmv MOVE_RIGHT  &kp PG_UP                                                                     &kp PERCENT   &kp KP_N4     &kp KP_N5     &kp KP_N6      &kp KP_PLUS            &none
               &trans  &kp K_APP           &none           &none            &none  &kp PG_DN  &kp CAPS  &kp TAB   &to 0     &to 0   &kp UP   &kp BSPC              &kp COMMA   &kp KP_N1     &kp KP_N2     &kp KP_N3     &kp KP_ENTER           &trans
            &kp LCTRL   &kp LGUI           &to 0  &msc SCRL_DOWN     &msc SCRL_UP             &kp BSPC  &kp DEL   &none  &kp LEFT  &kp DEL  &kp RIGHT                           &kp LEFT        &kp UP     &kp RIGHT            &to 0     &kp KP_ENTER
            >;
        };

        layer_Reversed {
            bindings = <
               &kp F6  &kp F7  &kp F8     &kp F9  &kp F10                                                                                    &kp F1    &kp F2  &kp F3  &kp F4     &kp F5
 &magic LAYER_Magic 0  &kp N6  &kp N7     &kp N8   &kp N9    &kp N0                                                                  &kp N1  &kp N2    &kp N3  &kp N4  &kp N5  &kp MINUS
                &none   &kp Y   &kp U      &kp I    &kp O     &kp P                                                                   &kp Q   &kp W     &kp E   &kp R   &kp T   &kp PIPE
                &none   &kp H   &kp J      &kp K    &kp L  &kp SEMI                                                                   &kp A   &kp S     &kp D   &kp F   &kp G      &none
                &to 0   &kp N   &kp M  &kp COMMA  &kp DOT  &kp FSLH  &kp LSHFT  &kp LGUI    &kp TAB  &kp LGUI  &kp RCTRL  &kp RSHFT   &kp Z   &kp X     &kp C   &kp V   &kp B      &to 0
                &none   &none   &to 0  &mkp LCLK  &kp RET            &kp SPACE   &kp RET  &kp QMARK   &kp DOT    &kp RET  &kp SPACE           &to 0  &kp RGUI   &to 0   &none      &none
            >;
        };

        layer_Media {
            bindings = <
                &none   &none   &none   &none   &none                                                                                                   &none   &none   &none   &none   &none
 &magic LAYER_Magic 0   &none   &none   &none   &none   &none                                                                                   &none   &none   &none   &none   &none   &none
                &none   &none   &none   &none   &none   &none                                                                                   &none   &none   &none   &none   &none   &none
                &none   &none   &none   &none   &none   &none                                                                                   &none   &none   &none   &none   &none   &none
                &none   &none   &none   &none   &none   &none  &kp C_VOL_DN  &kp K_MUTE  &kp C_VOL_UP  &kp C_VOL_DN  &kp C_MUTE  &kp C_VOL_UP   &none   &none   &none   &none   &none   &none
                &none   &none   &none   &none   &none            &kp C_PREV    &kp K_PP    &kp C_NEXT    &kp C_PREV    &kp C_PP    &kp C_NEXT           &none   &none   &none   &to 0   &none
            >;
        };

        layer_Magic {
            bindings = <
 &bootloader            &bt_0            &bt_1            &bt_2            &bt_3                                                                                              &none   &none   &none   &none  &bootloader
       &none            &to 2            &to 3            &to 5            &to 6            &to 7                                                             &none           &none   &none   &none   &to 0        &none
       &none  &rgb_ug RGB_SPI  &rgb_ug RGB_SAI  &rgb_ug RGB_HUI  &rgb_ug RGB_BRI  &rgb_ug RGB_TOG                                                             &none           &none   &none   &none   &none        &none
       &none  &rgb_ug RGB_SPD  &rgb_ug RGB_SAD  &rgb_ug RGB_HUD  &rgb_ug RGB_BRD  &rgb_ug RGB_EFF                                                             &none           &none   &none   &none   &none        &none
       &none            &none            &none            &none            &none       &sys_reset   &bt_2   &bt_3         &none   &none   &none   &none  &sys_reset           &none   &none   &none   &none        &none
       &none            &none            &to 0            &none       &bt BT_CLR                    &bt_0   &bt_1  &out OUT_USB   &none   &none   &none              &bt BT_CLR_ALL   &none   &to 0   &to 0        &to 6
            >;
        };

        layer_DefaultLayout {
            bindings = <
   &kp ESC    &kp F2    &kp F3     &kp F4     &kp F5                                                                                &kp F6     &kp F7      &kp F8   &kp F10    &kp F12
 &kp GRAVE    &kp N1    &kp N2     &kp N3     &kp N4  &kp N5                                                              &kp N6    &kp N7     &kp N8      &kp N9    &kp N0   &kp LBKT
   &kp TAB     &kp Q     &kp W      &kp E      &kp R   &kp T                                                               &kp Y     &kp U      &kp I       &kp O     &kp P   &kp LBKT
  &kp CAPS     &kp A     &kp S      &kp D      &kp F   &kp G                                                               &kp H     &kp J      &kp K       &kp L  &kp SEMI    &kp SQT
 &kp LSHFT     &kp Z     &kp X      &kp C      &kp V   &kp B    &kp DEL    &to 0     &to 0    &to 0     &to 0    &kp DEL   &kp N     &kp M  &kp COMMA     &kp DOT  &kp FSLH  &kp RSHFT
 &kp LCTRL  &kp LGUI  &kp LALT  &mkp LCLK  &mkp LCLK          &kp SPACE  &kp RET  &kp FSLH  &kp DOT  &kp BSPC  &kp SPACE          &kp RALT   &kp RGUI  &kp C_MENU     &to 0    &kp RET
            >;
        };

        layer_Factory {
            bindings = <
               &kp F1    &kp F2   &kp F3    &kp F4     &kp F5                                                                                  &kp F6     &kp F7    &kp F8    &kp F9    &kp F10
            &kp EQUAL    &kp N1   &kp N2    &kp N3     &kp N4  &kp N5                                                                  &kp N6  &kp N7     &kp N8    &kp N9    &kp N0  &kp MINUS
              &kp TAB     &kp Q    &kp W     &kp E      &kp R   &kp T                                                                   &kp Y   &kp U      &kp I     &kp O     &kp P   &kp PIPE
              &kp ESC     &kp A    &kp S     &kp D      &kp F   &kp G                                                                   &kp H   &kp J      &kp K     &kp L  &kp SEMI    &kp SQT
            &kp GRAVE     &kp Z    &kp X     &kp C      &kp V   &kp B  &kp LSHFT  &kp LCTRL     &to 0  &kp LGUI  &kp RIGHT  &kp RSHFT   &kp N   &kp M  &kp COMMA   &kp DOT  &kp FSLH  &kp PG_UP
 &magic LAYER_Magic 0  &kp HOME  &kp END  &kp LEFT  &kp RIGHT           &kp BSPC    &kp DEL  &kp LALT  &kp RALT    &kp RET  &kp SPACE          &kp UP   &kp DOWN  &kp LBKT     &to 0  &kp PG_DN
            >;
        };

    };
};
